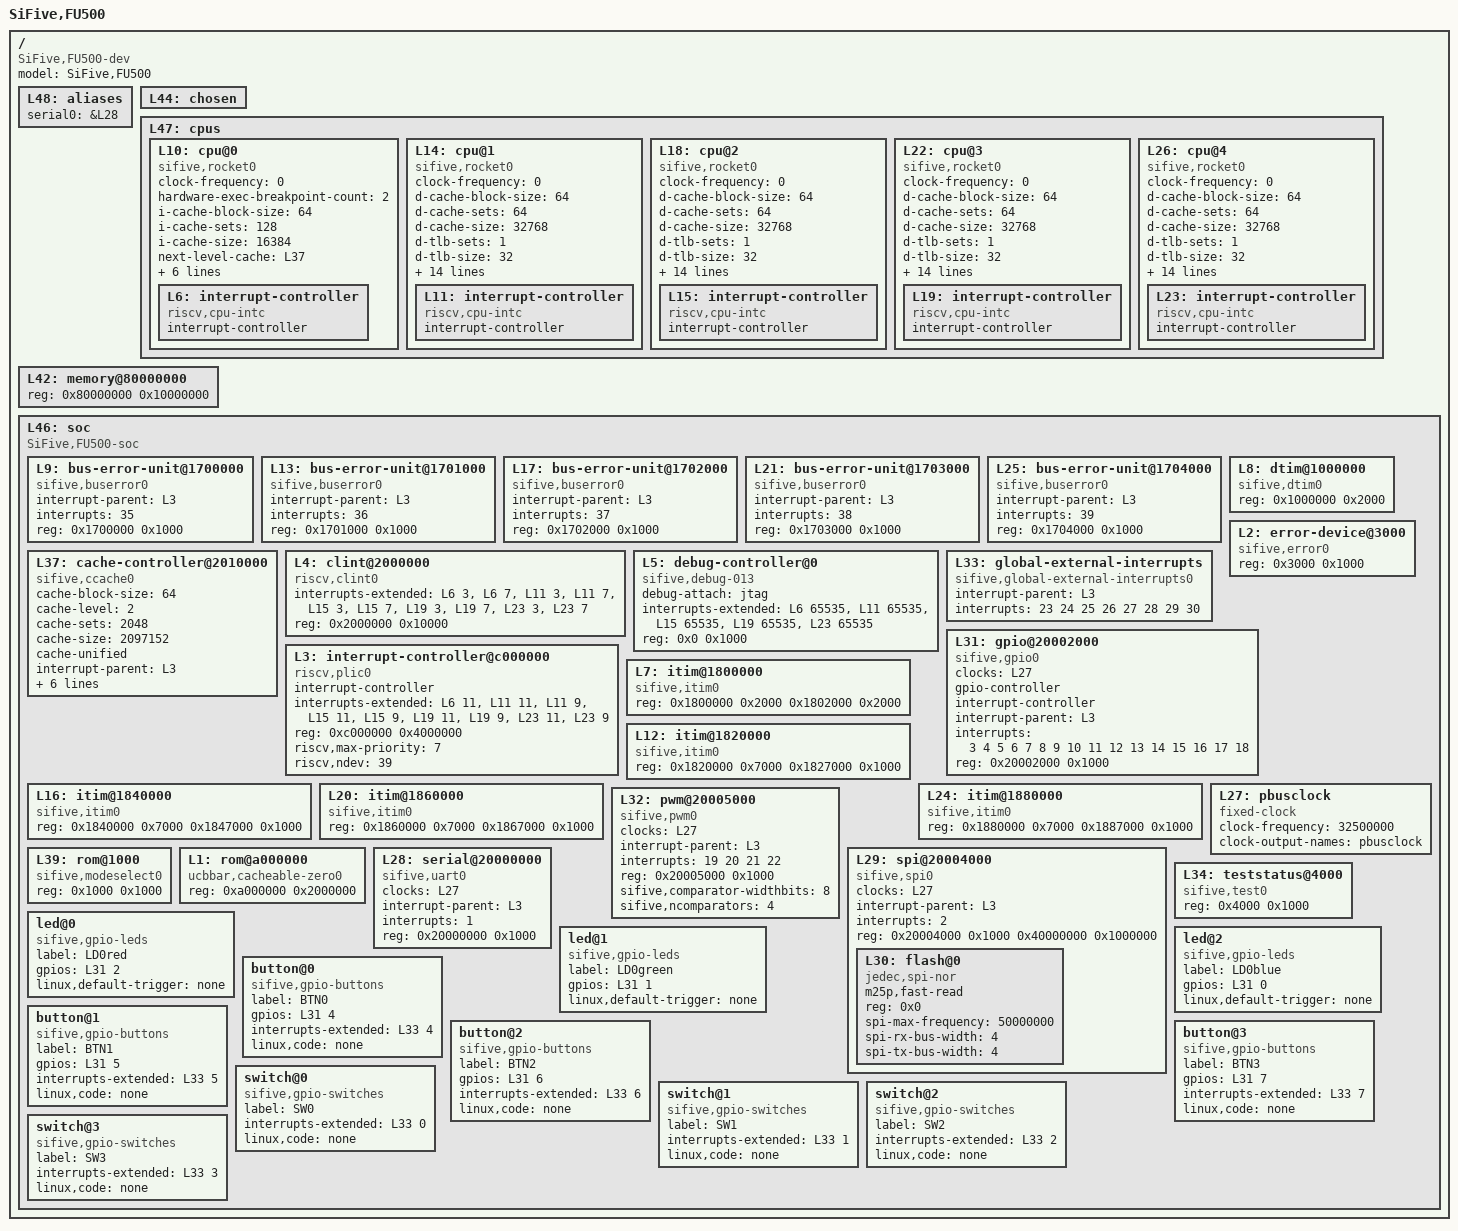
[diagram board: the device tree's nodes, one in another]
/dts-v1/;

/ {
	#address-cells = <1>;
	#size-cells = <1>;
	compatible = "SiFive,FU500-dev", "fu500-dev", "sifive-dev";
	model = "SiFive,FU500";
	L48: aliases {
		serial0 = &L28;
	};
	L44: chosen {
	};
	L47: cpus {
		#address-cells = <1>;
		#size-cells = <0>;
		L10: cpu@0 {
			clock-frequency = <0>;
			compatible = "sifive,rocket0", "riscv";
			device_type = "cpu";
			hardware-exec-breakpoint-count = <2>;
			i-cache-block-size = <64>;
			i-cache-sets = <128>;
			i-cache-size = <16384>;
			next-level-cache = <&L37>;
			reg = <0x0>;
			riscv,isa = "rv64imac";
			riscv,pmpregions = <8>;
			sifive,dtim = <&L8>;
			sifive,itim = <&L7>;
			status = "okay";
			timebase-frequency = <32500000>;
			L6: interrupt-controller {
				#interrupt-cells = <1>;
				compatible = "riscv,cpu-intc";
				interrupt-controller;
			};
		};
		L14: cpu@1 {
			clock-frequency = <0>;
			compatible = "sifive,rocket0", "riscv";
			d-cache-block-size = <64>;
			d-cache-sets = <64>;
			d-cache-size = <32768>;
			d-tlb-sets = <1>;
			d-tlb-size = <32>;
			device_type = "cpu";
			hardware-exec-breakpoint-count = <2>;
			i-cache-block-size = <64>;
			i-cache-sets = <64>;
			i-cache-size = <32768>;
			i-tlb-sets = <1>;
			i-tlb-size = <32>;
			mmu-type = "riscv,sv39";
			next-level-cache = <&L37>;
			reg = <0x1>;
			riscv,isa = "rv64imafdc";
			riscv,pmpregions = <8>;
			sifive,itim = <&L12>;
			status = "okay";
			timebase-frequency = <32500000>;
			tlb-split;
			L11: interrupt-controller {
				#interrupt-cells = <1>;
				compatible = "riscv,cpu-intc";
				interrupt-controller;
			};
		};
		L18: cpu@2 {
			clock-frequency = <0>;
			compatible = "sifive,rocket0", "riscv";
			d-cache-block-size = <64>;
			d-cache-sets = <64>;
			d-cache-size = <32768>;
			d-tlb-sets = <1>;
			d-tlb-size = <32>;
			device_type = "cpu";
			hardware-exec-breakpoint-count = <2>;
			i-cache-block-size = <64>;
			i-cache-sets = <64>;
			i-cache-size = <32768>;
			i-tlb-sets = <1>;
			i-tlb-size = <32>;
			mmu-type = "riscv,sv39";
			next-level-cache = <&L37>;
			reg = <0x2>;
			riscv,isa = "rv64imafdc";
			riscv,pmpregions = <8>;
			sifive,itim = <&L16>;
			status = "okay";
			timebase-frequency = <32500000>;
			tlb-split;
			L15: interrupt-controller {
				#interrupt-cells = <1>;
				compatible = "riscv,cpu-intc";
				interrupt-controller;
			};
		};
		L22: cpu@3 {
			clock-frequency = <0>;
			compatible = "sifive,rocket0", "riscv";
			d-cache-block-size = <64>;
			d-cache-sets = <64>;
			d-cache-size = <32768>;
			d-tlb-sets = <1>;
			d-tlb-size = <32>;
			device_type = "cpu";
			hardware-exec-breakpoint-count = <2>;
			i-cache-block-size = <64>;
			i-cache-sets = <64>;
			i-cache-size = <32768>;
			i-tlb-sets = <1>;
			i-tlb-size = <32>;
			mmu-type = "riscv,sv39";
			next-level-cache = <&L37>;
			reg = <0x3>;
			riscv,isa = "rv64imafdc";
			riscv,pmpregions = <8>;
			sifive,itim = <&L20>;
			status = "okay";
			timebase-frequency = <32500000>;
			tlb-split;
			L19: interrupt-controller {
				#interrupt-cells = <1>;
				compatible = "riscv,cpu-intc";
				interrupt-controller;
			};
		};
		L26: cpu@4 {
			clock-frequency = <0>;
			compatible = "sifive,rocket0", "riscv";
			d-cache-block-size = <64>;
			d-cache-sets = <64>;
			d-cache-size = <32768>;
			d-tlb-sets = <1>;
			d-tlb-size = <32>;
			device_type = "cpu";
			hardware-exec-breakpoint-count = <2>;
			i-cache-block-size = <64>;
			i-cache-sets = <64>;
			i-cache-size = <32768>;
			i-tlb-sets = <1>;
			i-tlb-size = <32>;
			mmu-type = "riscv,sv39";
			next-level-cache = <&L37>;
			reg = <0x4>;
			riscv,isa = "rv64imafdc";
			riscv,pmpregions = <8>;
			sifive,itim = <&L24>;
			status = "okay";
			timebase-frequency = <32500000>;
			tlb-split;
			L23: interrupt-controller {
				#interrupt-cells = <1>;
				compatible = "riscv,cpu-intc";
				interrupt-controller;
			};
		};
	};
	L42: memory@80000000 {
		device_type = "memory";
		reg = <0x80000000 0x10000000>;
	};
	L46: soc {
		#address-cells = <1>;
		#size-cells = <1>;
		compatible = "SiFive,FU500-soc", "fu500-soc", "sifive-soc", "simple-bus";
		ranges;
		L9: bus-error-unit@1700000 {
			compatible = "sifive,buserror0";
			interrupt-parent = <&L3>;
			interrupts = <35>;
			reg = <0x1700000 0x1000>;
			reg-names = "control";
		};
		L13: bus-error-unit@1701000 {
			compatible = "sifive,buserror0";
			interrupt-parent = <&L3>;
			interrupts = <36>;
			reg = <0x1701000 0x1000>;
			reg-names = "control";
		};
		L17: bus-error-unit@1702000 {
			compatible = "sifive,buserror0";
			interrupt-parent = <&L3>;
			interrupts = <37>;
			reg = <0x1702000 0x1000>;
			reg-names = "control";
		};
		L21: bus-error-unit@1703000 {
			compatible = "sifive,buserror0";
			interrupt-parent = <&L3>;
			interrupts = <38>;
			reg = <0x1703000 0x1000>;
			reg-names = "control";
		};
		L25: bus-error-unit@1704000 {
			compatible = "sifive,buserror0";
			interrupt-parent = <&L3>;
			interrupts = <39>;
			reg = <0x1704000 0x1000>;
			reg-names = "control";
		};
		L37: cache-controller@2010000 {
			cache-block-size = <64>;
			cache-level = <2>;
			cache-sets = <2048>;
			cache-size = <2097152>;
			cache-unified;
			compatible = "sifive,ccache0", "cache";
			interrupt-parent = <&L3>;
			interrupts = <31 32 33 34>;
			next-level-cache = <&L1 &L42>;
			reg = <0x2010000 0x1000 0x8000000 0x200000>;
			reg-names = "control", "sideband";
			sifive,a-mshr-count = <12>;
			sifive,bank-count = <4>;
			sifive,ecc-granularity = <8>;
		};
		L4: clint@2000000 {
			compatible = "riscv,clint0";
			interrupts-extended = <&L6 3 &L6 7 &L11 3 &L11 7 &L15 3 &L15 7 &L19 3 &L19 7 &L23 3 &L23 7>;
			reg = <0x2000000 0x10000>;
			reg-names = "control";
		};
		L5: debug-controller@0 {
			compatible = "sifive,debug-013", "riscv,debug-013";
			debug-attach = "jtag";
			interrupts-extended = <&L6 65535 &L11 65535 &L15 65535 &L19 65535 &L23 65535>;
			reg = <0x0 0x1000>;
			reg-names = "control";
		};
		L8: dtim@1000000 {
			compatible = "sifive,dtim0";
			reg = <0x1000000 0x2000>;
			reg-names = "mem";
		};
		L2: error-device@3000 {
			compatible = "sifive,error0";
			reg = <0x3000 0x1000>;
		};
		L33: global-external-interrupts {
			compatible = "sifive,global-external-interrupts0";
			interrupt-parent = <&L3>;
			interrupts = <23 24 25 26 27 28 29 30>;
		};
		L31: gpio@20002000 {
			#gpio-cells = <2>;
			#interrupt-cells = <2>;
			clocks = <&L27>;
			compatible = "sifive,gpio0", "sifive,gpio1";
			gpio-controller;
			interrupt-controller;
			interrupt-parent = <&L3>;
			interrupts = <3 4 5 6 7 8 9 10 11 12 13 14 15 16 17 18>;
			reg = <0x20002000 0x1000>;
			reg-names = "control";
		};
		L3: interrupt-controller@c000000 {
			#interrupt-cells = <1>;
			compatible = "riscv,plic0";
			interrupt-controller;
			interrupts-extended = <&L6 11 &L11 11 &L11 9 &L15 11 &L15 9 &L19 11 &L19 9 &L23 11 &L23 9>;
			reg = <0xc000000 0x4000000>;
			reg-names = "control";
			riscv,max-priority = <7>;
			riscv,ndev = <39>;
		};
		L7: itim@1800000 {
			compatible = "sifive,itim0";
			reg = <0x1800000 0x2000 0x1802000 0x2000>;
			reg-names = "mem", "control";
		};
		L12: itim@1820000 {
			compatible = "sifive,itim0";
			reg = <0x1820000 0x7000 0x1827000 0x1000>;
			reg-names = "mem", "control";
		};
		L16: itim@1840000 {
			compatible = "sifive,itim0";
			reg = <0x1840000 0x7000 0x1847000 0x1000>;
			reg-names = "mem", "control";
		};
		L20: itim@1860000 {
			compatible = "sifive,itim0";
			reg = <0x1860000 0x7000 0x1867000 0x1000>;
			reg-names = "mem", "control";
		};
		L24: itim@1880000 {
			compatible = "sifive,itim0";
			reg = <0x1880000 0x7000 0x1887000 0x1000>;
			reg-names = "mem", "control";
		};
		L27: pbusclock {
			#clock-cells = <0>;
			clock-frequency = <32500000>;
			clock-output-names = "pbusclock";
			compatible = "fixed-clock";
		};
		L32: pwm@20005000 {
			clocks = <&L27>;
			compatible = "sifive,pwm0";
			interrupt-parent = <&L3>;
			interrupts = <19 20 21 22>;
			reg = <0x20005000 0x1000>;
			reg-names = "control";
			sifive,comparator-widthbits = <8>;
			sifive,ncomparators = <4>;
		};
		L39: rom@1000 {
			compatible = "sifive,modeselect0";
			reg = <0x1000 0x1000>;
			reg-names = "mem";
		};
		L1: rom@a000000 {
			compatible = "ucbbar,cacheable-zero0";
			reg = <0xa000000 0x2000000>;
		};
		L28: serial@20000000 {
			clocks = <&L27>;
			compatible = "sifive,uart0";
			interrupt-parent = <&L3>;
			interrupts = <1>;
			reg = <0x20000000 0x1000>;
			reg-names = "control";
		};
		L29: spi@20004000 {
			#address-cells = <1>;
			#size-cells = <0>;
			clocks = <&L27>;
			compatible = "sifive,spi0";
			interrupt-parent = <&L3>;
			interrupts = <2>;
			reg = <0x20004000 0x1000 0x40000000 0x1000000>;
			reg-names = "control", "mem";
			L30: flash@0 {
				compatible = "jedec,spi-nor";
				m25p,fast-read;
				reg = <0x0>;
				spi-max-frequency = <50000000>;
				spi-rx-bus-width = <4>;
				spi-tx-bus-width = <4>;
			};
		};
		L34: teststatus@4000 {
			compatible = "sifive,test0";
			reg = <0x4000 0x1000>;
			reg-names = "control";
		};
				led@0 {
						compatible = "sifive,gpio-leds";
						label = "LD0red";
						gpios = <&L31 2>;
						linux,default-trigger = "none";
				};
				led@1 {
						compatible = "sifive,gpio-leds";
						label = "LD0green";
						gpios = <&L31 1>;
						linux,default-trigger = "none";
				};
				led@2 {
						compatible = "sifive,gpio-leds";
						label = "LD0blue";
						gpios = <&L31 0>;
						linux,default-trigger = "none";
				};
				button@0 {
						compatible = "sifive,gpio-buttons";
						label = "BTN0";
						gpios = <&L31 4>;
						interrupts-extended = <&L33 4>;
						linux,code = "none";
				};
				button@1 {
						compatible = "sifive,gpio-buttons";
						label = "BTN1";
						gpios = <&L31 5>;
						interrupts-extended = <&L33 5>;
						linux,code = "none";
				};
				button@2 {
						compatible = "sifive,gpio-buttons";
						label = "BTN2";
						gpios = <&L31 6>;
						interrupts-extended = <&L33 6>;
						linux,code = "none";
				};
				button@3 {
						compatible = "sifive,gpio-buttons";
						label = "BTN3";
						gpios = <&L31 7>;
						interrupts-extended = <&L33 7>;
						linux,code = "none";
				};
				switch@0 {
						compatible = "sifive,gpio-switches";
						label = "SW0";
						interrupts-extended = <&L33 0>;
						linux,code = "none";
				};
				switch@1 {
						compatible = "sifive,gpio-switches";
						label = "SW1";
						interrupts-extended = <&L33 1>;
						linux,code = "none";
				};
				switch@2 {
						compatible = "sifive,gpio-switches";
						label = "SW2";
						interrupts-extended = <&L33 2>;
						linux,code = "none";
				};
				switch@3 {
						compatible = "sifive,gpio-switches";
						label = "SW3";
						interrupts-extended = <&L33 3>;
						linux,code = "none";
				};

	};
};
